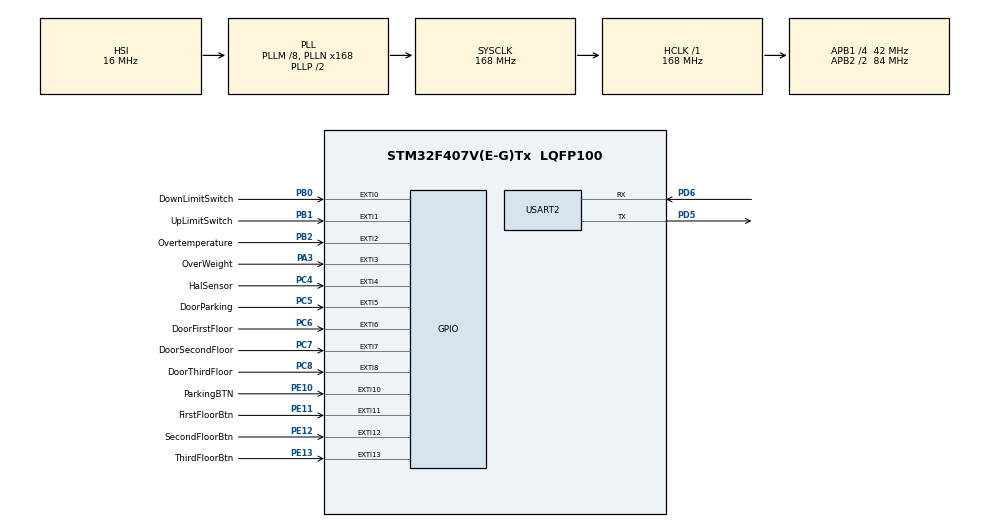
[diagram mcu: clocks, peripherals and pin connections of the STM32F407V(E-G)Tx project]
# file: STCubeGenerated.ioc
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Dma.Request0=USART2_TX
Dma.USART2_TX.0.Direction=DMA_MEMORY_TO_PERIPH
Dma.USART2_TX.0.FIFOMode=DMA_FIFOMODE_DISABLE
Dma.USART2_TX.0.Instance=DMA1_Stream6
Dma.USART2_TX.0.MemDataAlignment=DMA_MDATAALIGN_BYTE
Dma.USART2_TX.0.MemInc=DMA_MINC_ENABLE
Dma.USART2_TX.0.Mode=DMA_NORMAL
Dma.USART2_TX.0.PeriphDataAlignment=DMA_PDATAALIGN_BYTE
Dma.USART2_TX.0.PeriphInc=DMA_PINC_DISABLE
Dma.USART2_TX.0.Priority=DMA_PRIORITY_LOW
Mcu.Family=STM32F4
Mcu.Name=STM32F407V(E-G)Tx
Mcu.Package=LQFP100
NVIC.DMA1_Stream6_IRQn=true\:0\:0\:false\:false\:true\:false
NVIC.EXTI0_IRQn=true\:1\:0\:true\:true\:true\:1\:true
NVIC.EXTI15_10_IRQn=true\:3\:0\:true\:true\:true\:6\:true
NVIC.EXTI1_IRQn=true\:1\:0\:true\:true\:true\:2\:true
NVIC.EXTI2_IRQn=true\:2\:0\:true\:true\:true\:3\:true
NVIC.EXTI3_IRQn=true\:2\:0\:true\:true\:true\:4\:true
NVIC.EXTI9_5_IRQn=true\:1\:0\:true\:true\:true\:5\:true
NVIC.PriorityGroup=NVIC_PRIORITYGROUP_4
NVIC.TIM2_IRQn=true\:0\:0\:false\:false\:true\:true
PA13.Mode=Serial_Wire
PA13.Signal=SYS_JTMS-SWDIO
PA14.Mode=Serial_Wire
PA14.Signal=SYS_JTCK-SWCLK
PA3.GPIO_Label=OverWeight
PA3.GPIO_ModeDefaultEXTI=GPIO_MODE_IT_RISING_FALLING
PA3.GPIO_PuPd=GPIO_PULLUP
PA3.Signal=GPXTI3
PB0.GPIO_Label=DownLimitSwitch
PB0.GPIO_ModeDefaultEXTI=GPIO_MODE_IT_RISING_FALLING
PB0.GPIO_PuPd=GPIO_PULLUP
PB0.Signal=GPXTI0
PB1.GPIO_Label=UpLimitSwitch
PB1.GPIO_ModeDefaultEXTI=GPIO_MODE_IT_RISING_FALLING
PB1.GPIO_PuPd=GPIO_PULLUP
PB1.Signal=GPXTI1
PB2.GPIO_Label=Overtemperature
PB2.GPIO_ModeDefaultEXTI=GPIO_MODE_IT_RISING_FALLING
PB2.GPIO_PuPd=GPIO_PULLUP
PB2.Signal=GPXTI2
PC4.GPIO_Label=HalSensor
PC4.GPIO_ModeDefaultEXTI=GPIO_MODE_IT_RISING_FALLING
PC4.GPIO_PuPd=GPIO_PULLUP
PC4.Signal=GPXTI4
PC5.GPIO_Label=DoorParking
PC5.GPIO_ModeDefaultEXTI=GPIO_MODE_IT_RISING_FALLING
PC5.GPIO_PuPd=GPIO_PULLUP
PC5.Signal=GPXTI5
PC6.GPIO_Label=DoorFirstFloor
PC6.GPIO_ModeDefaultEXTI=GPIO_MODE_IT_RISING_FALLING
PC6.GPIO_PuPd=GPIO_PULLUP
PC6.Signal=GPXTI6
PC7.GPIO_Label=DoorSecondFloor
PC7.GPIO_ModeDefaultEXTI=GPIO_MODE_IT_RISING_FALLING
PC7.GPIO_PuPd=GPIO_PULLUP
PC7.Signal=GPXTI7
PC8.GPIO_Label=DoorThirdFloor
PC8.GPIO_ModeDefaultEXTI=GPIO_MODE_IT_RISING_FALLING
PC8.GPIO_PuPd=GPIO_PULLUP
PC8.Signal=GPXTI8
PD5.Mode=Asynchronous
PD5.Signal=USART2_TX
PD6.Mode=Asynchronous
PD6.Signal=USART2_RX
PE10.GPIO_Label=ParkingBTN
PE10.GPIO_ModeDefaultEXTI=GPIO_MODE_IT_FALLING
PE10.GPIO_PuPd=GPIO_PULLUP
PE10.Signal=GPXTI10
PE11.GPIO_Label=FirstFloorBtn
PE11.GPIO_ModeDefaultEXTI=GPIO_MODE_IT_FALLING
PE11.GPIO_PuPd=GPIO_PULLUP
PE11.Signal=GPXTI11
PE12.GPIO_Label=SecondFloorBtn
PE12.GPIO_ModeDefaultEXTI=GPIO_MODE_IT_FALLING
PE12.GPIO_PuPd=GPIO_PULLUP
PE12.Signal=GPXTI12
PE13.GPIO_Label=ThirdFloorBtn
PE13.GPIO_ModeDefaultEXTI=GPIO_MODE_IT_FALLING
PE13.GPIO_PuPd=GPIO_PULLUP
PE13.Signal=GPXTI13
ProjectManager.HeapSize=0x200
ProjectManager.StackSize=0x400
ProjectManager.TargetToolchain=MDK-ARM V5
RCC.48MHZClocksFreq_Value=84000000
RCC.AHBFreq_Value=168000000
RCC.APB1CLKDivider=RCC_HCLK_DIV4
RCC.APB1Freq_Value=42000000
RCC.APB1TimFreq_Value=84000000
RCC.APB2CLKDivider=RCC_HCLK_DIV2
RCC.APB2Freq_Value=84000000
RCC.APB2TimFreq_Value=168000000
RCC.CortexFreq_Value=168000000
RCC.HCLKFreq_Value=168000000
RCC.HSE_VALUE=25000000
RCC.HSI_VALUE=16000000
RCC.LSE_VALUE=32768
RCC.PLLM=8
RCC.PLLN=168
RCC.SYSCLKFreq_VALUE=168000000
RCC.SYSCLKSource=RCC_SYSCLKSOURCE_PLLCLK
RCC.VCOOutputFreq_Value=336000000
TIM2.Period=40000
TIM2.Prescaler=8399
USART2.VirtualMode=VM_ASYNC
VP_TIM2_VS_ClockSourceINT.Mode=Internal
board=custom

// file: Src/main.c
/**
  ******************************************************************************
  * @file           : main.c
  * @brief          : Main program body
  ******************************************************************************
  ** This notice applies to any and all portions of this file
  * that are not between comment pairs USER CODE BEGIN and
  * USER CODE END. Other portions of this file, whether
  * inserted by the user or by software development tools
  * are owned by their respective copyright owners.
  *
  * COPYRIGHT(c) 2019 STMicroelectronics
  *
  * Redistribution and use in source and binary forms, with or without modification,
  * are permitted provided that the following conditions are met:
  *   1. Redistributions of source code must retain the above copyright notice,
  *      this list of conditions and the following disclaimer.
  *   2. Redistributions in binary form must reproduce the above copyright notice,
  *      this list of conditions and the following disclaimer in the documentation
  *      and/or other materials provided with the distribution.
  *   3. Neither the name of STMicroelectronics nor the names of its contributors
  *      may be used to endorse or promote products derived from this software
  *      without specific prior written permission.
  *
  * THIS SOFTWARE IS PROVIDED BY THE COPYRIGHT HOLDERS AND CONTRIBUTORS "AS IS"
  * AND ANY EXPRESS OR IMPLIED WARRANTIES, INCLUDING, BUT NOT LIMITED TO, THE
  * IMPLIED WARRANTIES OF MERCHANTABILITY AND FITNESS FOR A PARTICULAR PURPOSE ARE
  * DISCLAIMED. IN NO EVENT SHALL THE COPYRIGHT HOLDER OR CONTRIBUTORS BE LIABLE
  * FOR ANY DIRECT, INDIRECT, INCIDENTAL, SPECIAL, EXEMPLARY, OR CONSEQUENTIAL
  * DAMAGES (INCLUDING, BUT NOT LIMITED TO, PROCUREMENT OF SUBSTITUTE GOODS OR
  * SERVICES; LOSS OF USE, DATA, OR PROFITS; OR BUSINESS INTERRUPTION) HOWEVER
  * CAUSED AND ON ANY THEORY OF LIABILITY, WHETHER IN CONTRACT, STRICT LIABILITY,
  * OR TORT (INCLUDING NEGLIGENCE OR OTHERWISE) ARISING IN ANY WAY OUT OF THE USE
  * OF THIS SOFTWARE, EVEN IF ADVISED OF THE POSSIBILITY OF SUCH DAMAGE.
  *
  ******************************************************************************
  */
#include "main.h"
#include "stm32f4xx_hal.h"
#include "dma.h"
#include "tim.h"
#include "usart.h"
#include "gpio.h"

/* USER CODE BEGIN Includes */
#define osObjectsPublic // define objects in main module
#include "cmsis_os.h"
#include "Threads.h"
#include "..\inc\ElevatorEvent.h"
#include "..\inc\ElevatorState.h"
/* USER CODE END Includes */

/* USER CODE BEGIN PV */
/* Private variables ---------------------------------------------------------*/
extern osThreadId dispatchThread;
extern Elevator_t me;
extern const osThreadDef_t os_thread_def_State_Dispatch;
/* USER CODE END PV */

void SystemClock_Config(void);
static void MX_NVIC_Init(void);

/* USER CODE BEGIN PFP */
/* Private function prototypes -----------------------------------------------*/

/* USER CODE END PFP */

int main(void)
{
  /* USER CODE BEGIN 1 */
osKernelInitialize();
  /* USER CODE END 1 */

  /* MCU Configuration----------------------------------------------------------*/

  /* Reset of all peripherals, Initializes the Flash interface and the Systick. */
  HAL_Init();

  /* Configure the system clock */
  SystemClock_Config();

  /* Initialize all configured peripherals */
  MX_GPIO_Init();
  MX_DMA_Init();
  MX_TIM2_Init();
  MX_USART2_UART_Init();

  /* Initialize interrupts */
  MX_NVIC_Init();
  /* USER CODE BEGIN 2 */
	//Construct state context and events
  Elevator_costructor(&me);

	// Init and create event queue
	Init_MailQueue();

	// create 'dispatch'thread and interrupt(event) thread functions that start executing,
	dispatchThread = osThreadCreate(osThread(State_Dispatch), (void *)0);
  osKernelStart();                      // start thread execution
  /* USER CODE END 2 */

  /* Infinite loop */
  while (1)
  {

  }

}

void SystemClock_Config(void)
{

  RCC_OscInitTypeDef RCC_OscInitStruct;
  RCC_ClkInitTypeDef RCC_ClkInitStruct;

    /**Configure the main internal regulator output voltage
    */
  __HAL_RCC_PWR_CLK_ENABLE();

  __HAL_PWR_VOLTAGESCALING_CONFIG(PWR_REGULATOR_VOLTAGE_SCALE1);

    /**Initializes the CPU, AHB and APB busses clocks
    */
  RCC_OscInitStruct.OscillatorType = RCC_OSCILLATORTYPE_HSI;
  RCC_OscInitStruct.HSIState = RCC_HSI_ON;
  RCC_OscInitStruct.HSICalibrationValue = 16;
  RCC_OscInitStruct.PLL.PLLState = RCC_PLL_ON;
  RCC_OscInitStruct.PLL.PLLSource = RCC_PLLSOURCE_HSI;
  RCC_OscInitStruct.PLL.PLLM = 8;
  RCC_OscInitStruct.PLL.PLLN = 168;
  RCC_OscInitStruct.PLL.PLLP = RCC_PLLP_DIV2;
  RCC_OscInitStruct.PLL.PLLQ = 4;
  if (HAL_RCC_OscConfig(&RCC_OscInitStruct) != HAL_OK)
  {
    _Error_Handler(__FILE__, __LINE__);
  }

    /**Initializes the CPU, AHB and APB busses clocks
    */
  RCC_ClkInitStruct.ClockType = RCC_CLOCKTYPE_HCLK|RCC_CLOCKTYPE_SYSCLK
                              |RCC_CLOCKTYPE_PCLK1|RCC_CLOCKTYPE_PCLK2;
  RCC_ClkInitStruct.SYSCLKSource = RCC_SYSCLKSOURCE_PLLCLK;
  RCC_ClkInitStruct.AHBCLKDivider = RCC_SYSCLK_DIV1;
  RCC_ClkInitStruct.APB1CLKDivider = RCC_HCLK_DIV4;
  RCC_ClkInitStruct.APB2CLKDivider = RCC_HCLK_DIV2;

  if (HAL_RCC_ClockConfig(&RCC_ClkInitStruct, FLASH_LATENCY_5) != HAL_OK)
  {
    _Error_Handler(__FILE__, __LINE__);
  }

    /**Configure the Systick interrupt time
    */
  HAL_SYSTICK_Config(HAL_RCC_GetHCLKFreq()/1000);

    /**Configure the Systick
    */
  HAL_SYSTICK_CLKSourceConfig(SYSTICK_CLKSOURCE_HCLK);

  /* SysTick_IRQn interrupt configuration */
  HAL_NVIC_SetPriority(SysTick_IRQn, 0, 0);
}

/**
  * @brief NVIC Configuration.
  * @retval None
  */
static void MX_NVIC_Init(void)
{
  /* EXTI0_IRQn interrupt configuration */
  HAL_NVIC_SetPriority(EXTI0_IRQn, 1, 0);
  HAL_NVIC_EnableIRQ(EXTI0_IRQn);
  /* EXTI1_IRQn interrupt configuration */
  HAL_NVIC_SetPriority(EXTI1_IRQn, 1, 0);
  HAL_NVIC_EnableIRQ(EXTI1_IRQn);
  /* EXTI2_IRQn interrupt configuration */
  HAL_NVIC_SetPriority(EXTI2_IRQn, 2, 0);
  HAL_NVIC_EnableIRQ(EXTI2_IRQn);
  /* EXTI3_IRQn interrupt configuration */
  HAL_NVIC_SetPriority(EXTI3_IRQn, 2, 0);
  HAL_NVIC_EnableIRQ(EXTI3_IRQn);
  /* EXTI9_5_IRQn interrupt configuration */
  HAL_NVIC_SetPriority(EXTI9_5_IRQn, 1, 0);
  HAL_NVIC_EnableIRQ(EXTI9_5_IRQn);
  /* EXTI15_10_IRQn interrupt configuration */
  HAL_NVIC_SetPriority(EXTI15_10_IRQn, 3, 0);
  HAL_NVIC_EnableIRQ(EXTI15_10_IRQn);
}

void _Error_Handler(char *file, int line)
{
  while(1)
  {
  }
}

/************************ (C) COPYRIGHT STMicroelectronics *****END OF FILE****/
